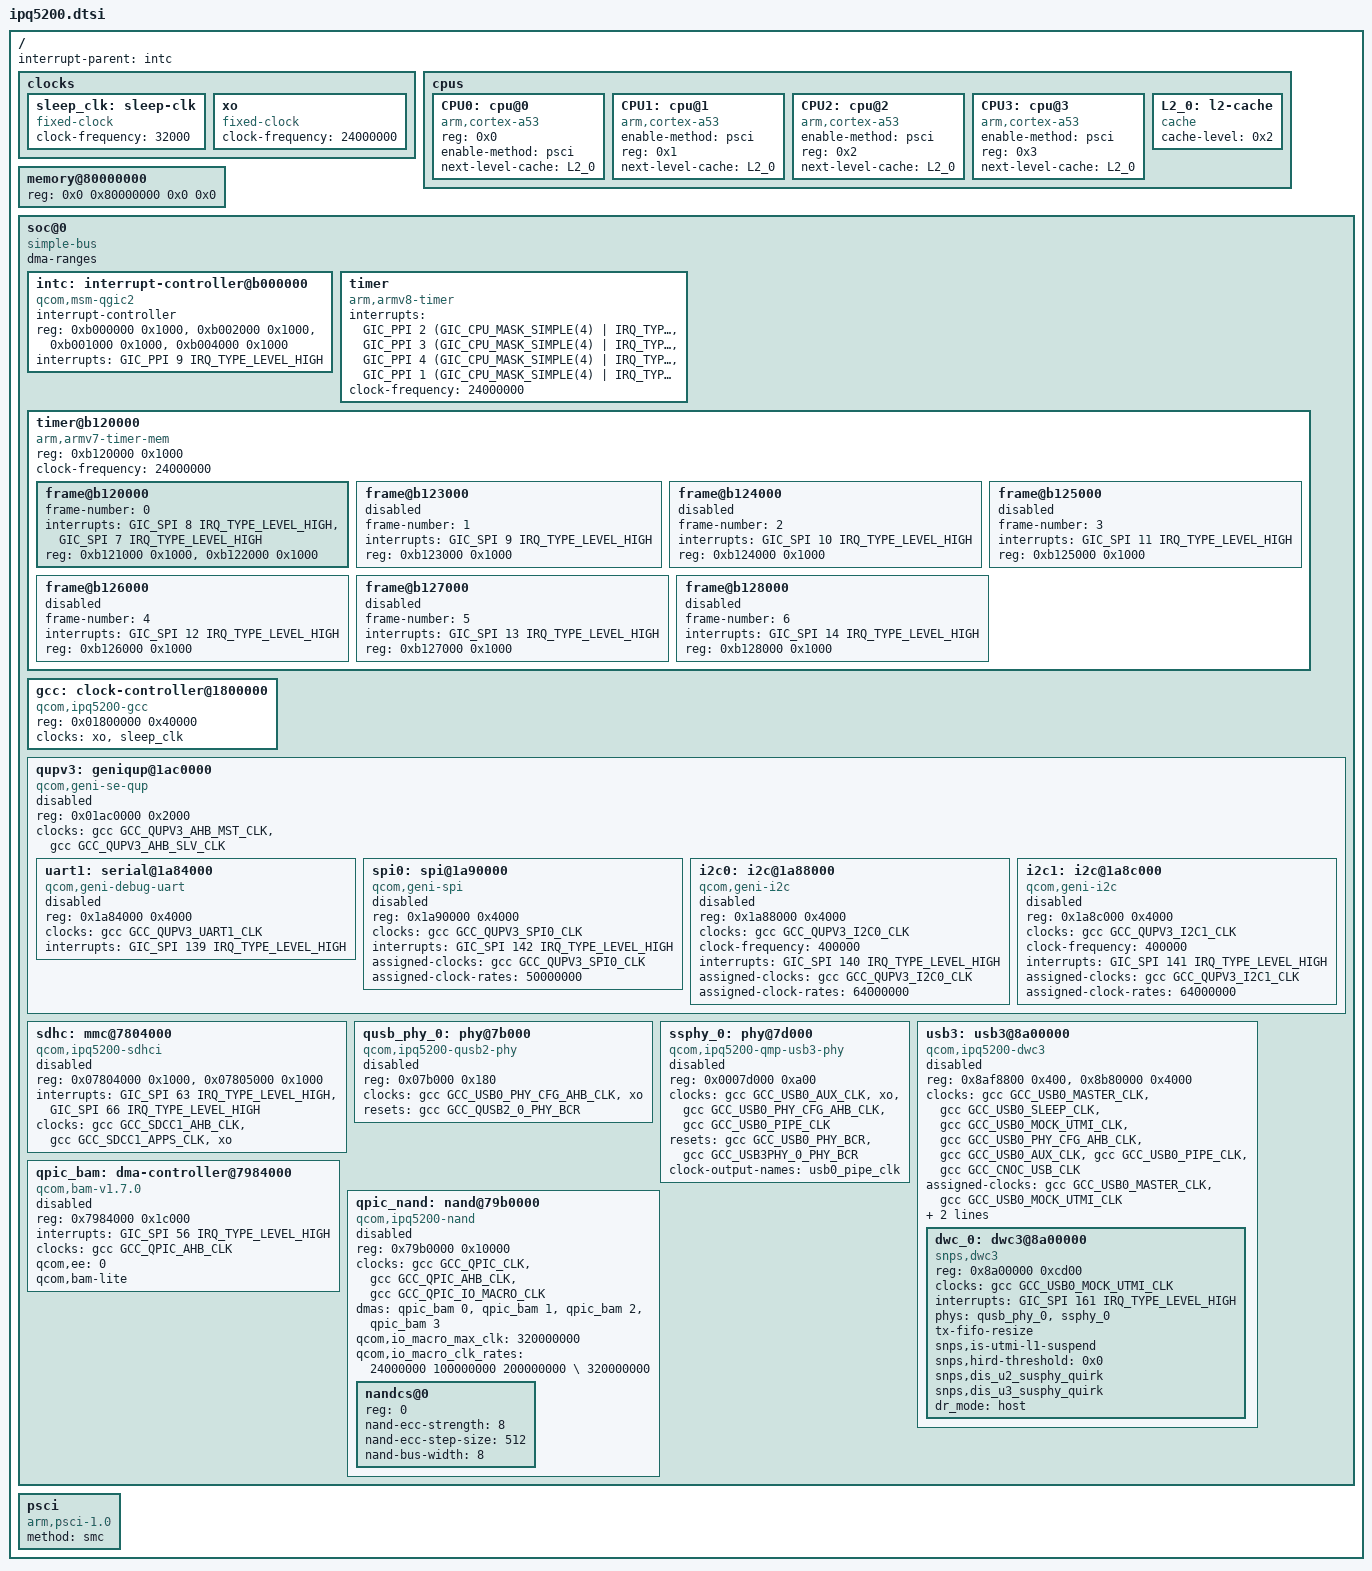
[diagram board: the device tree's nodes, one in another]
// SPDX-License-Identifier: (GPL-2.0+ OR BSD-3-Clause)
/*
 * IPQ5200 device tree source
 *
 * Copyright (c) 2020-2021 The Linux Foundation. All rights reserved.
 * Copyright (c) Qualcomm Technologies, Inc. and/or its subsidiaries.
 */

#include <dt-bindings/clock/qcom,ipq5200-gcc.h>
#include <dt-bindings/reset/qcom,ipq5200-gcc.h>
#include <dt-bindings/interrupt-controller/arm-gic.h>

/ {
	#address-cells = <2>;
	#size-cells = <2>;
	interrupt-parent = <&intc>;

	clocks {
		sleep_clk: sleep-clk {
			compatible = "fixed-clock";
			clock-frequency = <32000>;
			#clock-cells = <0>;
		};

		xo: xo {
			compatible = "fixed-clock";
			clock-frequency = <24000000>;
			#clock-cells = <0>;
		};
	};

	cpus: cpus {
		#address-cells = <1>;
		#size-cells = <0>;

		CPU0: cpu@0 {
			device_type = "cpu";
			compatible = "arm,cortex-a53";
			reg = <0x0>;
			enable-method = "psci";
			next-level-cache = <&L2_0>;
		};

		CPU1: cpu@1 {
			device_type = "cpu";
			compatible = "arm,cortex-a53";
			enable-method = "psci";
			reg = <0x1>;
			next-level-cache = <&L2_0>;
		};

		CPU2: cpu@2 {
			device_type = "cpu";
			compatible = "arm,cortex-a53";
			enable-method = "psci";
			reg = <0x2>;
			next-level-cache = <&L2_0>;
		};

		CPU3: cpu@3 {
			device_type = "cpu";
			compatible = "arm,cortex-a53";
			enable-method = "psci";
			reg = <0x3>;
			next-level-cache = <&L2_0>;
		};

		L2_0: l2-cache {
			compatible = "cache";
			cache-level = <0x2>;
		};
	};

	memory@80000000 {
		device_type = "memory";
		/* We expect the bootloader to fill in the size */
		reg = <0x0 0x80000000 0x0 0x0 >;
	};

	soc@0 {
		compatible = "simple-bus";
		#address-cells = <1>;
		#size-cells = <1>;
		ranges = <0 0 0 0xffffffff>;
		dma-ranges;

		intc: interrupt-controller@b000000 {
			compatible = "qcom,msm-qgic2";
			interrupt-controller;
			#interrupt-cells = <0x3>;
			reg = <0xb000000 0x1000>,  /*GICD*/
				<0xb002000 0x1000>,  /*GICC*/
				<0xb001000 0x1000>,  /*GICH*/
				<0xb004000 0x1000>;  /*GICV*/
			interrupts = <GIC_PPI 9 IRQ_TYPE_LEVEL_HIGH>;
		};

		timer {
			compatible = "arm,armv8-timer";
			interrupts = <GIC_PPI 2 (GIC_CPU_MASK_SIMPLE(4) | IRQ_TYPE_LEVEL_LOW)>,
				<GIC_PPI 3 (GIC_CPU_MASK_SIMPLE(4) | IRQ_TYPE_LEVEL_LOW)>,
				<GIC_PPI 4 (GIC_CPU_MASK_SIMPLE(4) | IRQ_TYPE_LEVEL_LOW)>,
				<GIC_PPI 1 (GIC_CPU_MASK_SIMPLE(4) | IRQ_TYPE_LEVEL_LOW)>;
			clock-frequency = <24000000>;
		};

		timer@b120000 {
			#address-cells = <1>;
			#size-cells = <1>;
			ranges;
			compatible = "arm,armv7-timer-mem";
			reg = <0xb120000 0x1000>;
			clock-frequency = <24000000>;

			frame@b120000 {
				frame-number = <0>;
				interrupts = <GIC_SPI 8 IRQ_TYPE_LEVEL_HIGH>,
					     <GIC_SPI 7 IRQ_TYPE_LEVEL_HIGH>;
				reg = <0xb121000 0x1000>,
				      <0xb122000 0x1000>;
			};

			frame@b123000 {
				frame-number = <1>;
				interrupts = <GIC_SPI 9 IRQ_TYPE_LEVEL_HIGH>;
				reg = <0xb123000 0x1000>;
				status = "disabled";
			};

			frame@b124000 {
				frame-number = <2>;
				interrupts = <GIC_SPI 10 IRQ_TYPE_LEVEL_HIGH>;
				reg = <0xb124000 0x1000>;
				status = "disabled";
			};

			frame@b125000 {
				frame-number = <3>;
				interrupts = <GIC_SPI 11 IRQ_TYPE_LEVEL_HIGH>;
				reg = <0xb125000 0x1000>;
				status = "disabled";
			};

			frame@b126000 {
				frame-number = <4>;
				interrupts = <GIC_SPI 12 IRQ_TYPE_LEVEL_HIGH>;
				reg = <0xb126000 0x1000>;
				status = "disabled";
			};

			frame@b127000 {
				frame-number = <5>;
				interrupts = <GIC_SPI 13 IRQ_TYPE_LEVEL_HIGH>;
				reg = <0xb127000 0x1000>;
				status = "disabled";
			};

			frame@b128000 {
				frame-number = <6>;
				interrupts = <GIC_SPI 14 IRQ_TYPE_LEVEL_HIGH>;
				reg = <0xb128000 0x1000>;
				status = "disabled";
			};
		};

		gcc: clock-controller@1800000 {
			compatible = "qcom,ipq5200-gcc";
			reg = <0x01800000 0x40000>;

			clocks = <&xo>,
				 <&sleep_clk>;
			#clock-cells = <1>;
			#reset-cells = <1>;
			#power-domain-cells = <1>;
		};

		qupv3: geniqup@1ac0000 {
			compatible = "qcom,geni-se-qup";
			reg = <0x01ac0000 0x2000>;
			clocks = <&gcc GCC_QUPV3_AHB_MST_CLK>,
				 <&gcc GCC_QUPV3_AHB_SLV_CLK>;
			clock-names = "m-ahb", "s-ahb";
			ranges;
			#address-cells = <1>;
			#size-cells = <1>;

			status = "disabled";

			uart1: serial@1a84000 {
				compatible = "qcom,geni-debug-uart";
				reg = <0x1a84000 0x4000>;
				clocks = <&gcc GCC_QUPV3_UART1_CLK>;
				clock-names = "se";
				interrupts = <GIC_SPI 139 IRQ_TYPE_LEVEL_HIGH>;
				status = "disabled";
			};

			spi0: spi@1a90000 {
				compatible = "qcom,geni-spi";
				reg = <0x1a90000 0x4000>;
				clocks = <&gcc GCC_QUPV3_SPI0_CLK>;
				clock-names = "se";
				interrupts = <GIC_SPI 142 IRQ_TYPE_LEVEL_HIGH>;
				assigned-clocks = <&gcc GCC_QUPV3_SPI0_CLK>;
				assigned-clock-rates = <50000000>;
				status = "disabled";
			};

			i2c0: i2c@1a88000 {
				compatible = "qcom,geni-i2c";
				reg = <0x1a88000 0x4000>;
				clocks = <&gcc GCC_QUPV3_I2C0_CLK>;
				clock-names = "se";
				clock-frequency = <400000>;
				interrupts = <GIC_SPI 140 IRQ_TYPE_LEVEL_HIGH>;
				assigned-clocks = <&gcc GCC_QUPV3_I2C0_CLK>;
				assigned-clock-rates = <64000000>;
				status = "disabled";
			};

			i2c1: i2c@1a8c000 {
				compatible = "qcom,geni-i2c";
				reg = <0x1a8c000 0x4000>;
				clocks = <&gcc GCC_QUPV3_I2C1_CLK>;
				clock-names = "se";
				clock-frequency = <400000>;
				interrupts = <GIC_SPI 141 IRQ_TYPE_LEVEL_HIGH>;
				assigned-clocks = <&gcc GCC_QUPV3_I2C1_CLK>;
				assigned-clock-rates = <64000000>;
				status = "disabled";
			};
		};

		sdhc: mmc@7804000 {
			compatible = "qcom,ipq5200-sdhci", "qcom,sdhci-msm-v5";
			reg = <0x07804000 0x1000>, <0x07805000 0x1000>;
			reg-names = "hc", "cqhci";

			interrupts = <GIC_SPI 63 IRQ_TYPE_LEVEL_HIGH>,
				     <GIC_SPI 66 IRQ_TYPE_LEVEL_HIGH>;
			interrupt-names = "hc_irq", "pwr_irq";

			clocks = <&gcc GCC_SDCC1_AHB_CLK>,
				 <&gcc GCC_SDCC1_APPS_CLK>,
				 <&xo>;
			clock-names = "iface", "core", "xo";

			status = "disabled";
		};

		qusb_phy_0: phy@7b000 {
			compatible = "qcom,ipq5200-qusb2-phy";
			reg = <0x07b000 0x180>;
			#phy-cells = <0>;

			clocks = <&gcc GCC_USB0_PHY_CFG_AHB_CLK>,
				<&xo>;
			clock-names = "cfg_ahb", "ref";

			resets = <&gcc GCC_QUSB2_0_PHY_BCR>;
			status = "disabled";
		};

		ssphy_0: phy@7d000 {
			compatible = "qcom,ipq5200-qmp-usb3-phy";
			reg = <0x0007d000 0xa00>;
			#phy-cells = <0>;

			clocks = <&gcc GCC_USB0_AUX_CLK>,
				 <&xo>,
				 <&gcc GCC_USB0_PHY_CFG_AHB_CLK>,
				 <&gcc GCC_USB0_PIPE_CLK>;
			clock-names = "aux",
				      "ref",
				      "cfg_ahb",
				      "pipe";

			resets = <&gcc GCC_USB0_PHY_BCR>,
				 <&gcc GCC_USB3PHY_0_PHY_BCR>;
			reset-names = "phy",
				      "phy_phy";

			#clock-cells = <0>;
			clock-output-names = "usb0_pipe_clk";

			status = "disabled";
		};

		usb3: usb3@8a00000 {
			compatible = "qcom,ipq5200-dwc3", "qcom,dwc3";
			reg = <0x8af8800 0x400>,
			      <0x8b80000 0x4000>;
			#address-cells = <1>;
			#size-cells = <1>;
			ranges;

			clocks = <&gcc GCC_USB0_MASTER_CLK>,
				<&gcc GCC_USB0_SLEEP_CLK>,
				<&gcc GCC_USB0_MOCK_UTMI_CLK>,
				<&gcc GCC_USB0_PHY_CFG_AHB_CLK>,
				<&gcc GCC_USB0_AUX_CLK>,
				<&gcc GCC_USB0_PIPE_CLK>,
				<&gcc GCC_CNOC_USB_CLK>;

			clock-names = "master",
				"sleep",
				"mock_utmi",
				"cfg_ahb_clk",
				"aux_clk",
				"pipe_clk",
				"cnoc_usb_clk";

			assigned-clocks = <&gcc GCC_USB0_MASTER_CLK>,
					  <&gcc GCC_USB0_MOCK_UTMI_CLK>;
			assigned-clock-rates = <200000000>,
					       <24000000>;

			resets = <&gcc GCC_USB_BCR>;
			status = "disabled";

			dwc_0: dwc3@8a00000 {
				compatible = "snps,dwc3";
				reg = <0x8a00000 0xcd00>;
				clocks = <&gcc GCC_USB0_MOCK_UTMI_CLK>;
				clock-names = "ref";
				interrupts = <GIC_SPI 161 IRQ_TYPE_LEVEL_HIGH>;
				phys = <&qusb_phy_0>, <&ssphy_0>;
				phy-names = "usb2-phy", "usb3-phy";
				tx-fifo-resize;
				snps,is-utmi-l1-suspend;
				snps,hird-threshold = /bits/ 8 <0x0>;
				snps,dis_u2_susphy_quirk;
				snps,dis_u3_susphy_quirk;
				dr_mode = "host";
			};
		};

		qpic_bam: dma-controller@7984000 {
			compatible = "qcom,bam-v1.7.0";
			reg = <0x7984000 0x1c000>;
			interrupts = <GIC_SPI 56 IRQ_TYPE_LEVEL_HIGH>;
			clocks = <&gcc GCC_QPIC_AHB_CLK>;
			clock-names = "bam_clk";
			#dma-cells = <1>;
			qcom,ee = <0>;
			qcom,bam-lite;
			status = "disabled";
		};

		qpic_nand: nand@79b0000 {
			compatible = "qcom,ipq5200-nand";
			reg = <0x79b0000 0x10000>;
			#address-cells = <1>;
			#size-cells = <0>;
			clocks = <&gcc GCC_QPIC_CLK>,
				 <&gcc GCC_QPIC_AHB_CLK>,
				 <&gcc GCC_QPIC_IO_MACRO_CLK>;
			clock-names = "core", "aon", "io_macro";

			dmas = <&qpic_bam 0>,
			       <&qpic_bam 1>,
			       <&qpic_bam 2>,
			       <&qpic_bam 3>;
			dma-names = "tx", "rx", "cmd", "sts";

			qcom,io_macro_max_clk = <320000000>;
			qcom,io_macro_clk_rates = <24000000 100000000 200000000 \
						   320000000>;

			status = "disabled";
			nandcs@0 {
				reg = <0>;
				#address-cells = <1>;
				#size-cells = <1>;

				nand-ecc-strength = <8>;
				nand-ecc-step-size = <512>;
				nand-bus-width = <8>;
			};
		};
	};

	psci {
		compatible = "arm,psci-1.0";
		method = "smc";
	};
};
